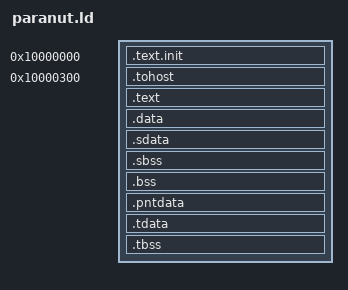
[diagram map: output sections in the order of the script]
/*************************************************************************

  This file is part of the ParaNut project.

  Copyright (C) 2019 Anna Pfuetzner <anna.pfuetzner@hs-augsburg.de>
                     Alexander Bahle <alexander.bahle@hs-augsburg.de>
      Hochschule Augsburg, University of Applied Sciences

  Description:
     This is the linker script used when building software for the ParaNut.

  Redistribution and use in source and binary forms, with or without modification,
  are permitted provided that the following conditions are met:

  1. Redistributions of source code must retain the above copyright notice, this 
     list of conditions and the following disclaimer.

  2. Redistributions in binary form must reproduce the above copyright notice,
     this list of conditions and the following disclaimer in the documentation and/or
     other materials provided with the distribution.

  THIS SOFTWARE IS PROVIDED BY THE COPYRIGHT HOLDERS AND CONTRIBUTORS "AS IS" AND 
  ANY EXPRESS OR IMPLIED WARRANTIES, INCLUDING, BUT NOT LIMITED TO, THE IMPLIED 
  WARRANTIES OF MERCHANTABILITY AND FITNESS FOR A PARTICULAR PURPOSE ARE 
  DISCLAIMED. IN NO EVENT SHALL THE COPYRIGHT HOLDER OR CONTRIBUTORS BE LIABLE FOR
  ANY DIRECT, INDIRECT, INCIDENTAL, SPECIAL, EXEMPLARY, OR CONSEQUENTIAL DAMAGES 
  (INCLUDING, BUT NOT LIMITED TO, PROCUREMENT OF SUBSTITUTE GOODS OR SERVICES; 
  LOSS OF USE, DATA, OR PROFITS; OR BUSINESS INTERRUPTION) HOWEVER CAUSED AND ON 
  ANY THEORY OF LIABILITY, WHETHER IN CONTRACT, STRICT LIABILITY, OR TORT 
  (INCLUDING NEGLIGENCE OR OTHERWISE) ARISING IN ANY WAY OUT OF THE USE OF THIS 
  SOFTWARE, EVEN IF ADVISED OF THE POSSIBILITY OF SUCH DAMAGE.

 *************************************************************************/

/*======================================================================*/
/* ParaNut linker script                                           */
/*======================================================================*/

/*----------------------------------------------------------------------*/
/* Setup                                                                */
/*----------------------------------------------------------------------*/

/* The OUTPUT_ARCH command specifies the machine architecture where the
   argument is one of the names used in the BFD library. More
   specifically one of the entires in bfd/cpu-mips.c */

OUTPUT_ARCH( "riscv" )
ENTRY(_start)

/*----------------------------------------------------------------------*/
/* Sections                                                             */
/*----------------------------------------------------------------------*/

SECTIONS
{

  /* text: test code section */
  . = 0x10000000;
  .text.init : { *(.text.init) }
  
  . = 0x10000300;
  .tohost : { *(.tohost) }

  . = ALIGN(0x10);
  .text : { *(.text) }

  /* data segment */
  . = ALIGN(0x1000);
  .data : { *(.data) }
  
  .sdata : {
    __global_pointer$ = . + 0x800;
    *(.srodata.cst16) *(.srodata.cst8) *(.srodata.cst4) *(.srodata.cst2) *(.srodata*)
    *(.sdata .sdata.* .gnu.linkonce.s.*)
  }

  /* bss segment */
   __bss_start = .;
  .sbss : {
    *(.sbss .sbss.* .gnu.linkonce.sb.*)
    *(.scommon)
  }
  .bss : { *(.bss) }
   __bss_end = .;

  /* ParaNut thread data segment (used for starting threads) */
  .pntdata : {
	*(.pntdata)
  }
 
 
  /* thread-local data segment */
  .tdata :
  {
    _tls_data = .;
    *(.tdata.begin)
    *(.tdata)
    *(.tdata.end)
  }
  .tbss :
  {
    *(.tbss)
    *(.tbss.end)
  }

  /* End of uninitalized data segement */
  _end = .;
}
